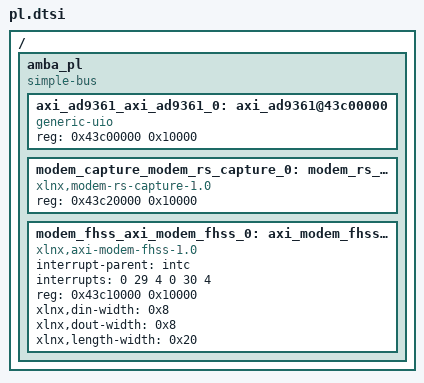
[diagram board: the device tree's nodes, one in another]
/*
 * CAUTION: This file is automatically generated by Xilinx.
 * Version: HSI 2016.2
 * Today is: Tue Nov 26 17:46:42 2019
*/


/ {
	amba_pl: amba_pl {
		#address-cells = <1>;
		#size-cells = <1>;
		compatible = "simple-bus";
		ranges ;
		axi_ad9361_axi_ad9361_0: axi_ad9361@43c00000 {
			compatible = "generic-uio";
			reg = <0x43c00000 0x10000>;
		};
		modem_capture_modem_rs_capture_0: modem_rs_capture@43c20000 {
			compatible = "xlnx,modem-rs-capture-1.0";
			reg = <0x43c20000 0x10000>;
		};
		modem_fhss_axi_modem_fhss_0: axi_modem_fhss@43c10000 {
			compatible = "xlnx,axi-modem-fhss-1.0";
			interrupt-parent = <&intc>;
			interrupts = <0 29 4 0 30 4>;
			reg = <0x43c10000 0x10000>;
			xlnx,din-width = <0x8>;
			xlnx,dout-width = <0x8>;
			xlnx,length-width = <0x20>;
		};
	};
};
